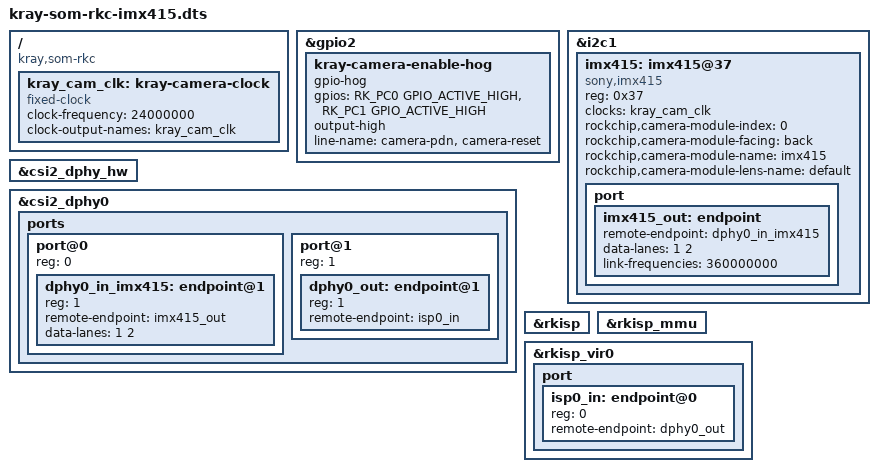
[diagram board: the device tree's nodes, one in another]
// SPDX-License-Identifier: (GPL-2.0+ OR MIT)
/*
 * Kray-SoM-RKC: Sony IMX415 8 MP (4K) camera module (Raspberry Pi style) on the CSI connector. Vendor kernel only.
 *
 *   /boot/armbianEnv.txt:  overlays=kray-som-rkc-imx415
 *
 * Raspberry Pi's imx415 driver (built in, userpatches/camera/rpi_imx415;
 * Rockchip's imx415 driver is switched off). Sensor on I2C1 at 0x37, two
 * MIPI CSI-2 lanes at 360 MHz (720 Mbit/s per lane, the rate for a 24 MHz
 * oscillator) through csi2_dphy0 into rkisp (rkisp_vir0). Camera power-down
 * (GPIO2_C0) and reset (GPIO2_C1) are held high.
 */

/dts-v1/;
/plugin/;

#include <dt-bindings/gpio/gpio.h>
#include <dt-bindings/pinctrl/rockchip.h>

/ {
	compatible = "kray,som-rkc", "rockchip,rk3566";

	fragment@0 {
		target-path = "/";
		__overlay__ {
			kray_cam_clk: kray-camera-clock {
				compatible = "fixed-clock";
				#clock-cells = <0>;
				clock-frequency = <24000000>;
				clock-output-names = "kray_cam_clk";
			};
		};
	};

	fragment@1 {
		target = <&gpio2>;
		__overlay__ {
			kray-camera-enable-hog {
				gpio-hog;
				/* GPIO2_C0: power-down (PDN), GPIO2_C1: reset */
				gpios = <RK_PC0 GPIO_ACTIVE_HIGH>, <RK_PC1 GPIO_ACTIVE_HIGH>;
				output-high;
				line-name = "camera-pdn", "camera-reset";
			};
		};
	};

	fragment@2 {
		target = <&i2c1>;
		__overlay__ {
			status = "okay";
			#address-cells = <1>;
			#size-cells = <0>;

			imx415: imx415@37 {
				compatible = "sony,imx415";
				reg = <0x37>;
				clocks = <&kray_cam_clk>;
				clock-names = "inck";
				rockchip,camera-module-index = <0>;
				rockchip,camera-module-facing = "back";
				rockchip,camera-module-name = "imx415";
				rockchip,camera-module-lens-name = "default";

				port {
					imx415_out: endpoint {
						remote-endpoint = <&dphy0_in_imx415>;
						data-lanes = <1 2>;
						link-frequencies = /bits/ 64 <360000000>;
					};
				};
			};
		};
	};

	fragment@3 {
		target = <&csi2_dphy_hw>;
		__overlay__ {
			status = "okay";
		};
	};

	fragment@4 {
		target = <&csi2_dphy0>;
		__overlay__ {
			status = "okay";

			ports {
				#address-cells = <1>;
				#size-cells = <0>;

				port@0 {
					reg = <0>;
					#address-cells = <1>;
					#size-cells = <0>;

					dphy0_in_imx415: endpoint@1 {
						reg = <1>;
						remote-endpoint = <&imx415_out>;
						data-lanes = <1 2>;
					};
				};

				port@1 {
					reg = <1>;
					#address-cells = <1>;
					#size-cells = <0>;

					dphy0_out: endpoint@1 {
						reg = <1>;
						remote-endpoint = <&isp0_in>;
					};
				};
			};
		};
	};

	fragment@5 {
		target = <&rkisp>;
		__overlay__ {
			status = "okay";
		};
	};

	fragment@6 {
		target = <&rkisp_mmu>;
		__overlay__ {
			status = "okay";
		};
	};

	fragment@7 {
		target = <&rkisp_vir0>;
		__overlay__ {
			status = "okay";

			port {
				#address-cells = <1>;
				#size-cells = <0>;

				isp0_in: endpoint@0 {
					reg = <0>;
					remote-endpoint = <&dphy0_out>;
				};
			};
		};
	};
};
